# DMAC2 register map
Registers from a debugger description file.
Registers are 64-bit, access not given, no defined reset value unless marked. A register's access mark holds for its fields unless they carry their own. Addresses are absolute; registers are grouped by the start of their names; lines under a group give offsets from that group; [hi:lo] are bit positions; {n}, {i} and the like mark numbered series; 'fields as' and 'values as' point back to an identical list; <NAME> marks a mode.

## DMAC2
{0x40105000+0x58*i} DMAC2/SAR{i} (i=0..7)
  [31:0] SAR
{0x40105008+0x58*i} DMAC2/DAR{i} (i=0..7)
  [31:0] DAR
{0x40105010+0x58*i} DMAC2/LLP{i} (i=0..7)
  [31:2] LOC
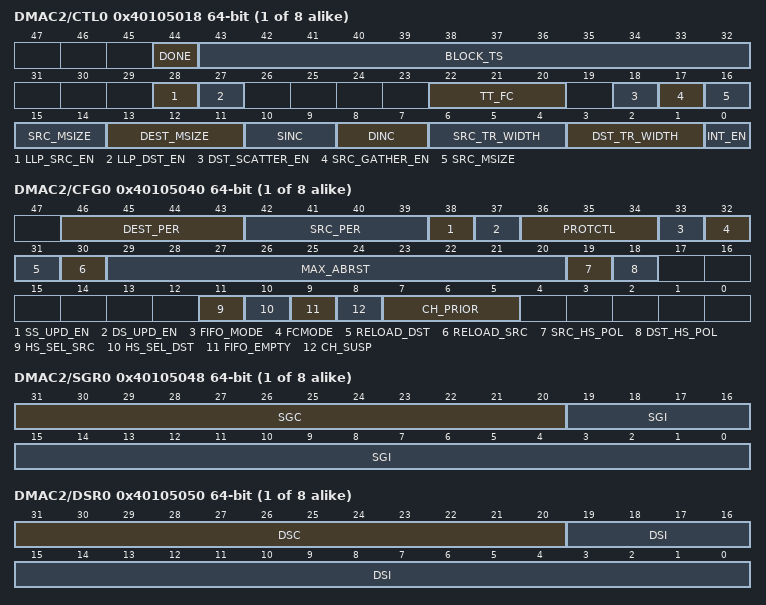
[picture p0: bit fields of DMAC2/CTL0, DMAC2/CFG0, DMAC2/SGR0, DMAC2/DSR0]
{0x40105018+0x58*i} DMAC2/CTL{i} (i=0..7)
  [44] DONE, [43:32] BLOCK_TS, [28] LLP_SRC_EN, [27] LLP_DST_EN, [22:20] TT_FC, [18] DST_SCATTER_EN, [17] SRC_GATHER_EN, [16:14] SRC_MSIZE, [13:11] DEST_MSIZE, [10:9] SINC, [8:7] DINC, [6:4] SRC_TR_WIDTH, [3:1] DST_TR_WIDTH, [0] INT_EN
{0x40105020+0x58*i} DMAC2/SSTAT{i} (i=0..7)
  [31:0] SSTAT
{0x40105028+0x58*i} DMAC2/DSTAT{i} (i=0..7)
  [31:0] DSTAT
{0x40105030+0x58*i} DMAC2/SSTATAR{i} (i=0..7)
  [31:0] SSTATAR
{0x40105038+0x58*i} DMAC2/DSTATAR{i} (i=0..7)
  [31:0] DSTATAR
{0x40105040+0x58*i} DMAC2/CFG{i} (i=0..7)
  [46:43] DEST_PER, [42:39] SRC_PER, [38] SS_UPD_EN, [37] DS_UPD_EN, [36:34] PROTCTL, [33] FIFO_MODE, [32] FCMODE, [31] RELOAD_DST, [30] RELOAD_SRC, [29:20] MAX_ABRST, [19] SRC_HS_POL, [18] DST_HS_POL, [11] HS_SEL_SRC, [10] HS_SEL_DST, [9] FIFO_EMPTY, [8] CH_SUSP, [7:5] CH_PRIOR
{0x40105048+0x58*i} DMAC2/SGR{i} (i=0..7)
  [31:20] SGC, [19:0] SGI
{0x40105050+0x58*i} DMAC2/DSR{i} (i=0..7)
  [31:20] DSC, [19:0] DSI
0x401052C0 DMAC2/RawTfr
  [7:0] RAW
0x401052C8 DMAC2/RawBlock
  [7:0] RAW
0x401052D0 DMAC2/RawSrcTran
  [7:0] RAW
0x401052D8 DMAC2/RawDstTran
  [7:0] RAW
0x401052E0 DMAC2/RawErr
  [7:0] RAW
0x401052E8 DMAC2/StatusTfr ro
  [7:0] STATUS
0x401052F0 DMAC2/StatusBlock ro
  [7:0] STATUS
0x401052F8 DMAC2/StatusSrcTran ro
  [7:0] STATUS
0x40105300 DMAC2/StatusDstTran ro
  [7:0] STATUS
0x40105308 DMAC2/StatusErr ro
  [7:0] STATUS
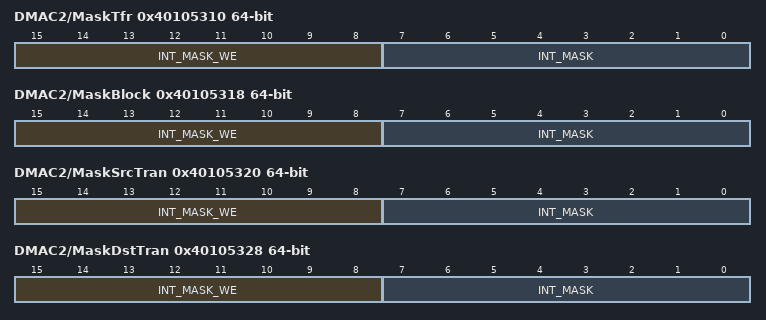
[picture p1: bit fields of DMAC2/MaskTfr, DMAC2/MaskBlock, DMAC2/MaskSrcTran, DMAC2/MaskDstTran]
0x40105310 DMAC2/MaskTfr
  [15:8] INT_MASK_WE, [7:0] INT_MASK
0x40105318 DMAC2/MaskBlock
  [15:8] INT_MASK_WE, [7:0] INT_MASK
0x40105320 DMAC2/MaskSrcTran
  [15:8] INT_MASK_WE, [7:0] INT_MASK
0x40105328 DMAC2/MaskDstTran
  [15:8] INT_MASK_WE, [7:0] INT_MASK
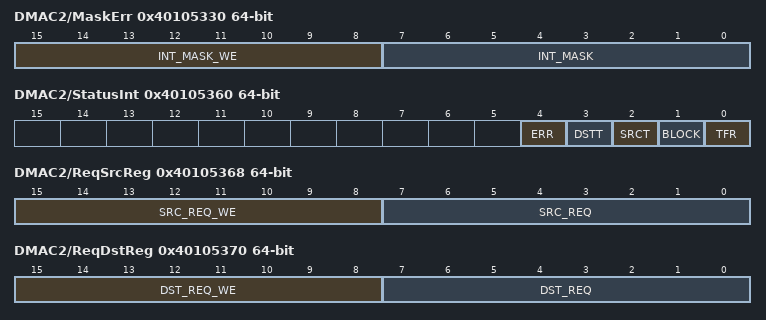
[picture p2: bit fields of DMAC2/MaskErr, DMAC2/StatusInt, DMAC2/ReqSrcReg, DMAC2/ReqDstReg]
0x40105330 DMAC2/MaskErr
  [15:8] INT_MASK_WE, [7:0] INT_MASK
0x40105338 DMAC2/ClearTfr wo
  [7:0] CLEAR
0x40105340 DMAC2/ClearBlock wo
  [7:0] CLEAR
0x40105348 DMAC2/ClearSrcTran wo
  [7:0] CLEAR
0x40105350 DMAC2/ClearDstTran wo
  [7:0] CLEAR
0x40105358 DMAC2/ClearErr wo
  [7:0] CLEAR
0x40105360 DMAC2/StatusInt ro
  [4] ERR, [3] DSTT, [2] SRCT, [1] BLOCK, [0] TFR
0x40105368 DMAC2/ReqSrcReg
  [15:8] SRC_REQ_WE, [7:0] SRC_REQ
0x40105370 DMAC2/ReqDstReg
  [15:8] DST_REQ_WE, [7:0] DST_REQ
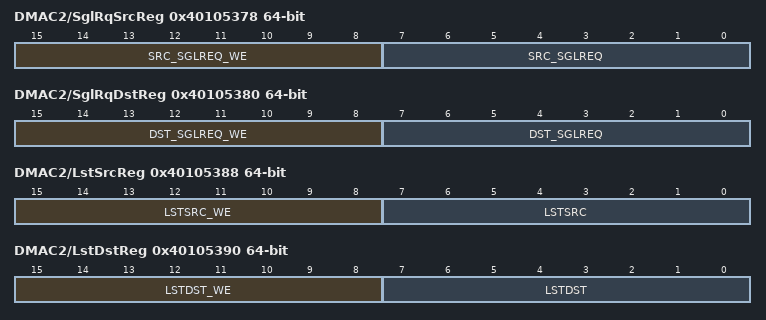
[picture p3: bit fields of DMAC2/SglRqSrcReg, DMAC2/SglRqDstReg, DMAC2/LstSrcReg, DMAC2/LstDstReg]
0x40105378 DMAC2/SglRqSrcReg
  [15:8] SRC_SGLREQ_WE, [7:0] SRC_SGLREQ
0x40105380 DMAC2/SglRqDstReg
  [15:8] DST_SGLREQ_WE, [7:0] DST_SGLREQ
0x40105388 DMAC2/LstSrcReg
  [15:8] LSTSRC_WE, [7:0] LSTSRC
0x40105390 DMAC2/LstDstReg
  [15:8] LSTDST_WE, [7:0] LSTDST
0x40105398 DMAC2/DmaCfgReg
  [0] DMA_EN
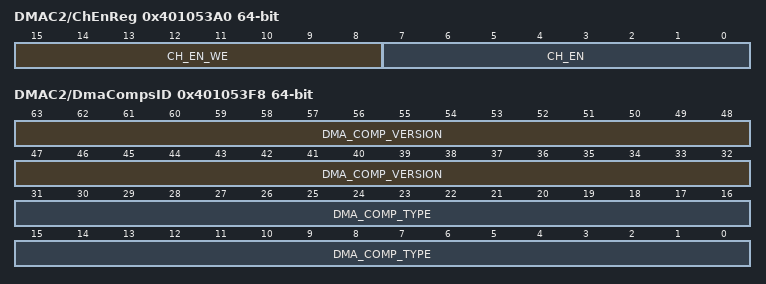
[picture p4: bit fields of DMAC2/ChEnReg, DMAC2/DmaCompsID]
0x401053A0 DMAC2/ChEnReg
  [15:8] CH_EN_WE, [7:0] CH_EN
0x401053A8 DMAC2/DmaIdReg ro
  [31:0] DMA_ID
0x401053B0 DMAC2/DmaTestReg
  [0] TEST_SLV_IF
0x401053F8 DMAC2/DmaCompsID ro
  [63:32] DMA_COMP_VERSION, [31:0] DMA_COMP_TYPE
